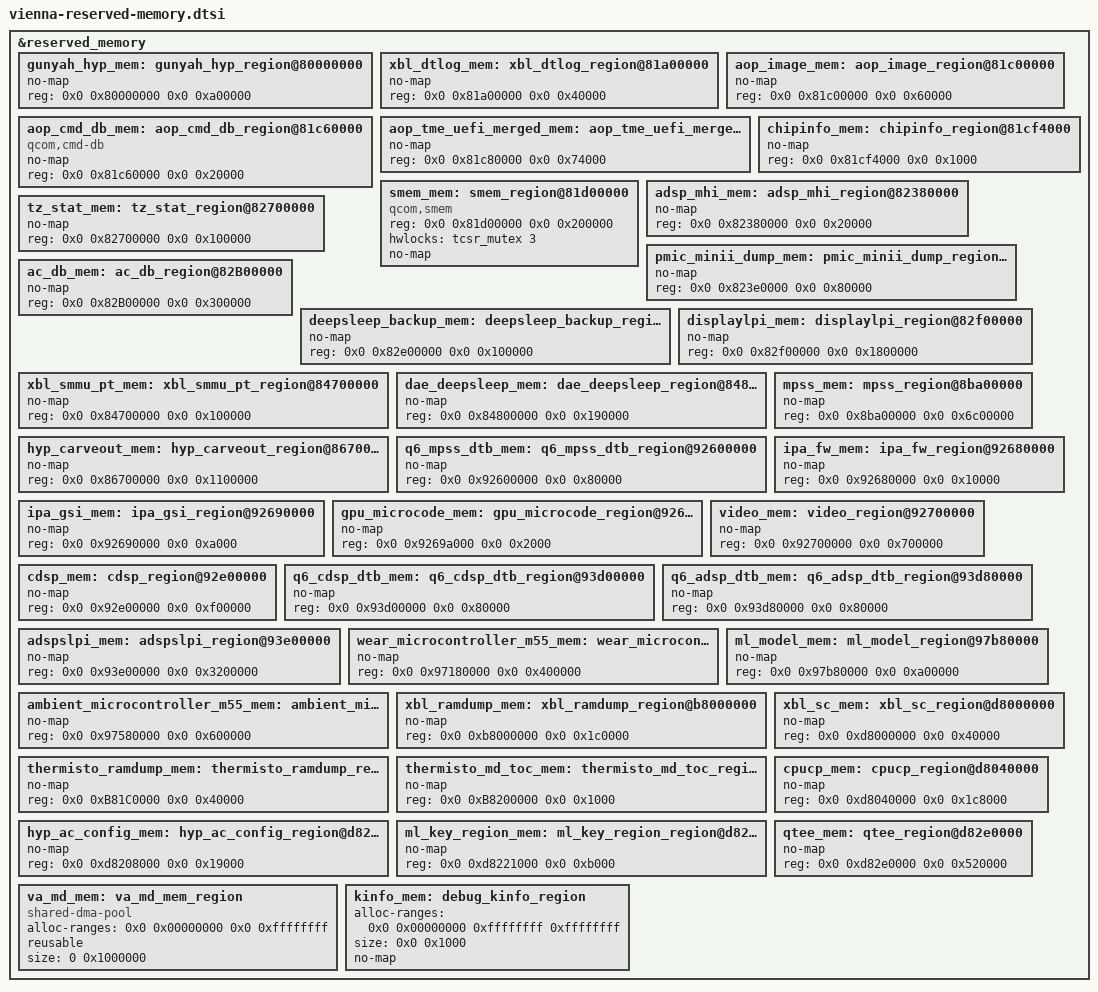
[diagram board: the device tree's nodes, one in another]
// SPDX-License-Identifier: BSD-3-Clause
/*
 * Copyright (c) Qualcomm Technologies, Inc. and/or its subsidiaries.
 */

&reserved_memory {
	#address-cells = <2>;
	#size-cells = <2>;
	ranges;

	gunyah_hyp_mem: gunyah_hyp_region@80000000 {
		no-map;
		reg = <0x0 0x80000000 0x0 0xa00000>;
	};

	/*
	 * hyp_tags_mem is dynamically removed from the RAM
	 * partition tables before boot occurs. Size of region
	 * varies.
	 */

	xbl_dtlog_mem: xbl_dtlog_region@81a00000 {
		no-map;
		reg = <0x0 0x81a00000 0x0 0x40000>;
	};

	aop_image_mem: aop_image_region@81c00000 {
		no-map;
		reg = <0x0 0x81c00000 0x0 0x60000>;
	};

	aop_cmd_db_mem: aop_cmd_db_region@81c60000 {
		compatible = "qcom,cmd-db";
		no-map;
		reg = <0x0 0x81c60000 0x0 0x20000>;
	};

	/* merged aop_config, tme_crash_dump, tme_log and uefi_log regions */
	aop_tme_uefi_merged_mem: aop_tme_uefi_merged_region@81c80000 {
		no-map;
		reg = <0x0 0x81c80000 0x0 0x74000>;
	};

	chipinfo_mem: chipinfo_region@81cf4000 {
		no-map;
		reg = <0x0 0x81cf4000 0x0 0x1000>;
	};

	/* secdata region can be reused by apps */
	smem_mem: smem_region@81d00000 {
		compatible = "qcom,smem";
		reg = <0x0 0x81d00000 0x0 0x200000>;
		hwlocks = <&tcsr_mutex 3>;
		no-map;
	};

	adsp_mhi_mem: adsp_mhi_region@82380000 {
		no-map;
		reg = <0x0 0x82380000 0x0 0x20000>;
	};

	pmic_minii_dump_mem: pmic_minii_dump_region@823e0000 {
		no-map;
		reg = <0x0 0x823e0000 0x0 0x80000>;
	};

	/* hyp_mem_database_mem is removed by HYP in the RAM partition table */

	tz_stat_mem: tz_stat_region@82700000 {
		no-map;
		reg = <0x0 0x82700000 0x0 0x100000>;
	};

	ac_db_mem: ac_db_region@82B00000 {
		no-map;
		reg = <0x0 0x82B00000 0x0 0x300000>;
	};

	deepsleep_backup_mem: deepsleep_backup_region@82e00000 {
		no-map;
		reg = <0x0 0x82e00000 0x0 0x100000>;
	};

	displaylpi_mem: displaylpi_region@82f00000 {
		no-map;
		reg = <0x0 0x82f00000 0x0 0x1800000>;
	};

	xbl_smmu_pt_mem: xbl_smmu_pt_region@84700000 {
		no-map;
		reg = <0x0 0x84700000 0x0 0x100000>;
	};

	dae_deepsleep_mem: dae_deepsleep_region@84800000 {
		no-map;
		reg = <0x0 0x84800000 0x0 0x190000>;
	};

	hyp_carveout_mem: hyp_carveout_region@86700000 {
		no-map;
		reg = <0x0 0x86700000 0x0 0x1100000>;
	};

	mpss_mem: mpss_region@8ba00000 {
		no-map;
		reg = <0x0 0x8ba00000 0x0 0x6c00000>;
	};

	q6_mpss_dtb_mem: q6_mpss_dtb_region@92600000 {
		no-map;
		reg = <0x0 0x92600000 0x0 0x80000>;
	};

	ipa_fw_mem: ipa_fw_region@92680000 {
		no-map;
		reg = <0x0 0x92680000 0x0 0x10000>;
	};

	ipa_gsi_mem: ipa_gsi_region@92690000 {
		no-map;
		reg = <0x0 0x92690000 0x0 0xa000>;
	};

	gpu_microcode_mem: gpu_microcode_region@9269a000 {
		no-map;
		reg = <0x0 0x9269a000 0x0 0x2000>;
	};

	video_mem: video_region@92700000 {
		no-map;
		reg = <0x0 0x92700000 0x0 0x700000>;
	};

	cdsp_mem: cdsp_region@92e00000 {
		no-map;
		reg = <0x0 0x92e00000 0x0 0xf00000>;
	};

	q6_cdsp_dtb_mem: q6_cdsp_dtb_region@93d00000 {
		no-map;
		reg = <0x0 0x93d00000 0x0 0x80000>;
	};

	q6_adsp_dtb_mem: q6_adsp_dtb_region@93d80000 {
		no-map;
		reg = <0x0 0x93d80000 0x0 0x80000>;
	};

	adspslpi_mem: adspslpi_region@93e00000 {
		no-map;
		reg = <0x0 0x93e00000 0x0 0x3200000>;
	};

	wear_microcontroller_m55_mem: wear_microcontroller_m55_region@97180000 {
		no-map;
		reg = <0x0 0x97180000 0x0 0x400000>;
	};

	ambient_microcontroller_m55_mem: ambient_microcontroller_m55_region@97580000 {
		no-map;
		reg = <0x0 0x97580000 0x0 0x600000>;
	};

	ml_model_mem: ml_model_region@97b80000 {
		no-map;
		reg = <0x0 0x97b80000 0x0 0xa00000>;
	};

	/* UEFI region at 0xa7000000 is reclaimed by Linux */

	xbl_ramdump_mem: xbl_ramdump_region@b8000000 {
		no-map;
		reg = <0x0 0xb8000000 0x0 0x1c0000>;
	};

	thermisto_ramdump_mem: thermisto_ramdump_region@B81C0000 {
		no-map;
		reg = <0x0 0xB81C0000 0x0 0x40000>;
	};

	thermisto_md_toc_mem: thermisto_md_toc_region@B8200000 {
		no-map;
		reg = <0x0 0xB8200000 0x0 0x1000>;
	};

	xbl_sc_mem: xbl_sc_region@d8000000 {
		no-map;
		reg = <0x0 0xd8000000 0x0 0x40000>;
	};

	cpucp_mem: cpucp_region@d8040000 {
		no-map;
		reg = <0x0 0xd8040000 0x0 0x1c8000>;
	};

	hyp_ac_config_mem: hyp_ac_config_region@d8208000 {
		no-map;
		reg = <0x0 0xd8208000 0x0 0x19000>;
	};

	ml_key_region_mem: ml_key_region_region@d8221000 {
		no-map;
		reg = <0x0 0xd8221000 0x0 0xb000>;
	};

	qtee_mem: qtee_region@d82e0000 {
		no-map;
		reg = <0x0 0xd82e0000 0x0 0x520000>;
	};

	va_md_mem: va_md_mem_region {
		compatible = "shared-dma-pool";
		alloc-ranges = <0x0 0x00000000 0x0 0xffffffff>;
		reusable;
		size = <0 0x1000000>;
	};

	kinfo_mem: debug_kinfo_region {
		alloc-ranges = <0x0 0x00000000 0xffffffff 0xffffffff>;
		size = <0x0 0x1000>;
		no-map;
	};

	/*
	 * ta/tags mem is dynamically removed from the RAM
	 * partition tables before boot occurs. Size of region
	 * varies.
	 */
};
